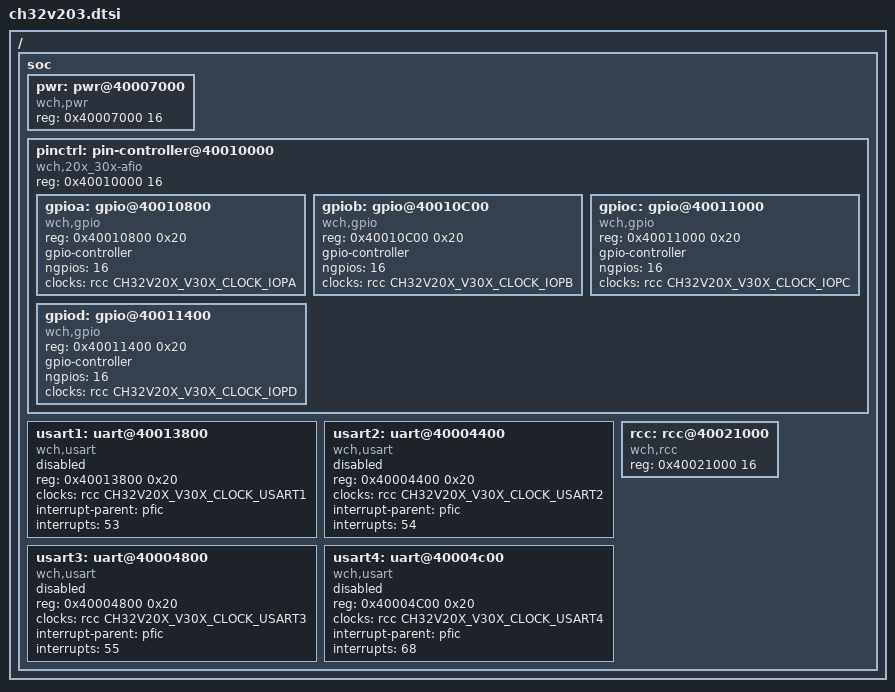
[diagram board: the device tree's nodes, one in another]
/*
 * Copyright (c) 2025 Jianxiong Gu <jianxiong.gu@outlook.com>
 *
 * SPDX-License-Identifier: Apache-2.0
 */

#include <wch/qingke-v4b.dtsi>
#include <zephyr/dt-bindings/gpio/gpio.h>
#include <zephyr/dt-bindings/i2c/i2c.h>
#include <zephyr/dt-bindings/clock/ch32v20x_30x-clocks.h>

/ {
	soc {
		pwr: pwr@40007000 {
			compatible = "wch,pwr";
			reg = <0x40007000 16>;
		};

		pinctrl: pin-controller@40010000 {
			compatible = "wch,20x_30x-afio";
			reg = <0x40010000 16>;
			#address-cells = <1>;
			#size-cells = <1>;

			gpioa: gpio@40010800 {
				compatible = "wch,gpio";
				reg = <0x40010800 0x20>;
				gpio-controller;
				#gpio-cells = <2>;
				ngpios = <16>;
				clocks = <&rcc CH32V20X_V30X_CLOCK_IOPA>;
			};

			gpiob: gpio@40010C00 {
				compatible = "wch,gpio";
				reg = <0x40010C00 0x20>;
				gpio-controller;
				#gpio-cells = <2>;
				ngpios = <16>;
				clocks = <&rcc CH32V20X_V30X_CLOCK_IOPB>;
			};

			gpioc: gpio@40011000 {
				compatible = "wch,gpio";
				reg = <0x40011000 0x20>;
				gpio-controller;
				#gpio-cells = <2>;
				ngpios = <16>;
				clocks = <&rcc CH32V20X_V30X_CLOCK_IOPC>;
			};

			gpiod: gpio@40011400 {
				compatible = "wch,gpio";
				reg = <0x40011400 0x20>;
				gpio-controller;
				#gpio-cells = <2>;
				ngpios = <16>;
				clocks = <&rcc CH32V20X_V30X_CLOCK_IOPD>;
			};
		};

		usart1: uart@40013800 {
			compatible = "wch,usart";
			reg = <0x40013800 0x20>;
			clocks = <&rcc CH32V20X_V30X_CLOCK_USART1>;
			interrupt-parent = <&pfic>;
			interrupts = <53>;
			status = "disabled";
		};

		usart2: uart@40004400 {
			compatible = "wch,usart";
			reg = <0x40004400 0x20>;
			clocks = <&rcc CH32V20X_V30X_CLOCK_USART2>;
			interrupt-parent = <&pfic>;
			interrupts = <54>;
			status = "disabled";
		};

		usart3: uart@40004800 {
			compatible = "wch,usart";
			reg = <0x40004800 0x20>;
			clocks = <&rcc CH32V20X_V30X_CLOCK_USART3>;
			interrupt-parent = <&pfic>;
			interrupts = <55>;
			status = "disabled";
		};

		usart4: uart@40004c00 {
			compatible = "wch,usart";
			reg = <0x40004C00 0x20>;
			clocks = <&rcc CH32V20X_V30X_CLOCK_USART4>;
			interrupt-parent = <&pfic>;
			interrupts = <68>;
			status = "disabled";
		};

		rcc: rcc@40021000 {
			compatible = "wch,rcc";
			reg = <0x40021000 16>;
			#clock-cells = <1>;
		};
	};
};
